# Espressif register map
File version: 1.0
CPU: Xtensa LX6 1, little endian, no MPU, FPU, 3 interrupt priority bits
Registers are 32-bit, access not given, reset 0x0 unless marked. A register's access mark holds for its fields unless they carry their own. Offsets are from the block's base; [hi:lo] are bit positions.

## I2S
Base 0x3FF4F000
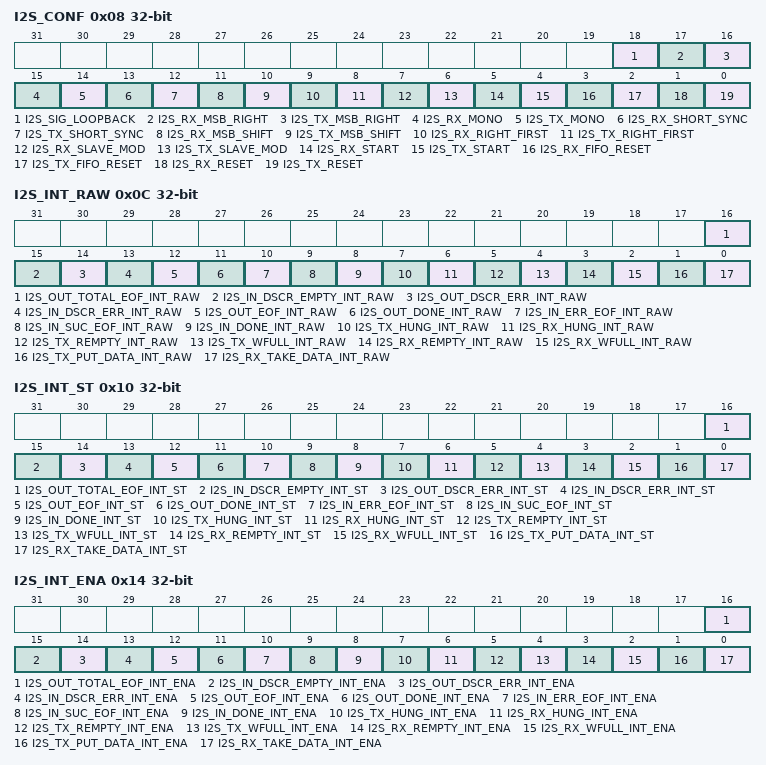
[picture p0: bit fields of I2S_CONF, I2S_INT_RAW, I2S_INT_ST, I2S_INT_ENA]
0x08 I2S_CONF
  [18] I2S_SIG_LOOPBACK, [17] I2S_RX_MSB_RIGHT, [16] I2S_TX_MSB_RIGHT, [15] I2S_RX_MONO, [14] I2S_TX_MONO, [13] I2S_RX_SHORT_SYNC, [12] I2S_TX_SHORT_SYNC, [11] I2S_RX_MSB_SHIFT, [10] I2S_TX_MSB_SHIFT, [9] I2S_RX_RIGHT_FIRST, [8] I2S_TX_RIGHT_FIRST, [7] I2S_RX_SLAVE_MOD, [6] I2S_TX_SLAVE_MOD, [5] I2S_RX_START, [4] I2S_TX_START, [3] I2S_RX_FIFO_RESET, [2] I2S_TX_FIFO_RESET, [1] I2S_RX_RESET, [0] I2S_TX_RESET
0x0C I2S_INT_RAW
  [16] I2S_OUT_TOTAL_EOF_INT_RAW, [15] I2S_IN_DSCR_EMPTY_INT_RAW, [14] I2S_OUT_DSCR_ERR_INT_RAW, [13] I2S_IN_DSCR_ERR_INT_RAW, [12] I2S_OUT_EOF_INT_RAW, [11] I2S_OUT_DONE_INT_RAW, [10] I2S_IN_ERR_EOF_INT_RAW, [9] I2S_IN_SUC_EOF_INT_RAW, [8] I2S_IN_DONE_INT_RAW, [7] I2S_TX_HUNG_INT_RAW, [6] I2S_RX_HUNG_INT_RAW, [5] I2S_TX_REMPTY_INT_RAW, [4] I2S_TX_WFULL_INT_RAW, [3] I2S_RX_REMPTY_INT_RAW, [2] I2S_RX_WFULL_INT_RAW, [1] I2S_TX_PUT_DATA_INT_RAW, [0] I2S_RX_TAKE_DATA_INT_RAW
0x10 I2S_INT_ST
  [16] I2S_OUT_TOTAL_EOF_INT_ST, [15] I2S_IN_DSCR_EMPTY_INT_ST, [14] I2S_OUT_DSCR_ERR_INT_ST, [13] I2S_IN_DSCR_ERR_INT_ST, [12] I2S_OUT_EOF_INT_ST, [11] I2S_OUT_DONE_INT_ST, [10] I2S_IN_ERR_EOF_INT_ST, [9] I2S_IN_SUC_EOF_INT_ST, [8] I2S_IN_DONE_INT_ST, [7] I2S_TX_HUNG_INT_ST, [6] I2S_RX_HUNG_INT_ST, [5] I2S_TX_REMPTY_INT_ST, [4] I2S_TX_WFULL_INT_ST, [3] I2S_RX_REMPTY_INT_ST, [2] I2S_RX_WFULL_INT_ST, [1] I2S_TX_PUT_DATA_INT_ST, [0] I2S_RX_TAKE_DATA_INT_ST
0x14 I2S_INT_ENA
  [16] I2S_OUT_TOTAL_EOF_INT_ENA, [15] I2S_IN_DSCR_EMPTY_INT_ENA, [14] I2S_OUT_DSCR_ERR_INT_ENA, [13] I2S_IN_DSCR_ERR_INT_ENA, [12] I2S_OUT_EOF_INT_ENA, [11] I2S_OUT_DONE_INT_ENA, [10] I2S_IN_ERR_EOF_INT_ENA, [9] I2S_IN_SUC_EOF_INT_ENA, [8] I2S_IN_DONE_INT_ENA, [7] I2S_TX_HUNG_INT_ENA, [6] I2S_RX_HUNG_INT_ENA, [5] I2S_TX_REMPTY_INT_ENA, [4] I2S_TX_WFULL_INT_ENA, [3] I2S_RX_REMPTY_INT_ENA, [2] I2S_RX_WFULL_INT_ENA, [1] I2S_TX_PUT_DATA_INT_ENA, [0] I2S_RX_TAKE_DATA_INT_ENA
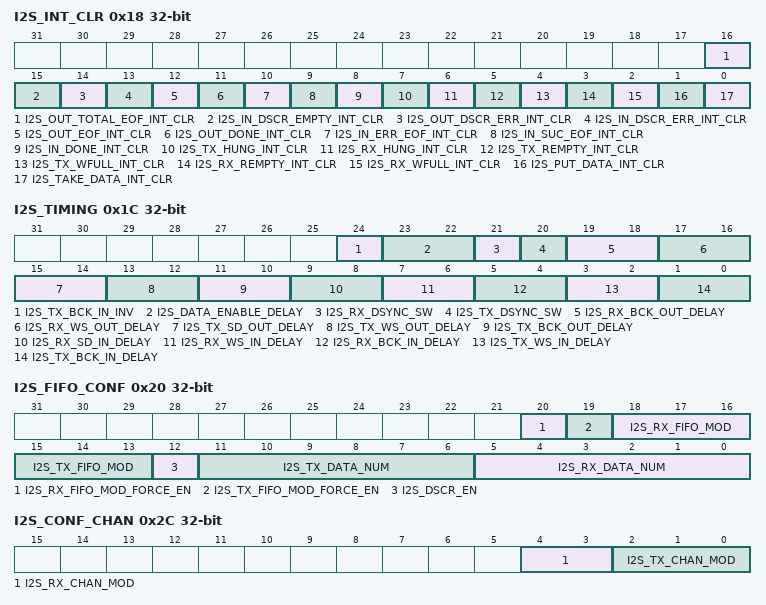
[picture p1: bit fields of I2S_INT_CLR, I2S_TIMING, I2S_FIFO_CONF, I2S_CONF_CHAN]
0x18 I2S_INT_CLR
  [16] I2S_OUT_TOTAL_EOF_INT_CLR, [15] I2S_IN_DSCR_EMPTY_INT_CLR, [14] I2S_OUT_DSCR_ERR_INT_CLR, [13] I2S_IN_DSCR_ERR_INT_CLR, [12] I2S_OUT_EOF_INT_CLR, [11] I2S_OUT_DONE_INT_CLR, [10] I2S_IN_ERR_EOF_INT_CLR, [9] I2S_IN_SUC_EOF_INT_CLR, [8] I2S_IN_DONE_INT_CLR, [7] I2S_TX_HUNG_INT_CLR, [6] I2S_RX_HUNG_INT_CLR, [5] I2S_TX_REMPTY_INT_CLR, [4] I2S_TX_WFULL_INT_CLR, [3] I2S_RX_REMPTY_INT_CLR, [2] I2S_RX_WFULL_INT_CLR, [1] I2S_PUT_DATA_INT_CLR, [0] I2S_TAKE_DATA_INT_CLR
0x1C I2S_TIMING
  [24] I2S_TX_BCK_IN_INV, [23:22] I2S_DATA_ENABLE_DELAY, [21] I2S_RX_DSYNC_SW, [20] I2S_TX_DSYNC_SW, [19:18] I2S_RX_BCK_OUT_DELAY, [17:16] I2S_RX_WS_OUT_DELAY, [15:14] I2S_TX_SD_OUT_DELAY, [13:12] I2S_TX_WS_OUT_DELAY, [11:10] I2S_TX_BCK_OUT_DELAY, [9:8] I2S_RX_SD_IN_DELAY, [7:6] I2S_RX_WS_IN_DELAY, [5:4] I2S_RX_BCK_IN_DELAY, [3:2] I2S_TX_WS_IN_DELAY, [1:0] I2S_TX_BCK_IN_DELAY
0x20 I2S_FIFO_CONF
  [20] I2S_RX_FIFO_MOD_FORCE_EN, [19] I2S_TX_FIFO_MOD_FORCE_EN, [18:16] I2S_RX_FIFO_MOD, [15:13] I2S_TX_FIFO_MOD, [12] I2S_DSCR_EN, [11:6] I2S_TX_DATA_NUM, [5:0] I2S_RX_DATA_NUM
0x24 I2S_RXEOF_NUM
  [31:0] I2S_RX_EOF_NUM
0x28 I2S_CONF_SIGLE_DATA
  [31:0] I2S_SIGLE_DATA
0x2C I2S_CONF_CHAN
  [4:3] I2S_RX_CHAN_MOD, [2:0] I2S_TX_CHAN_MOD
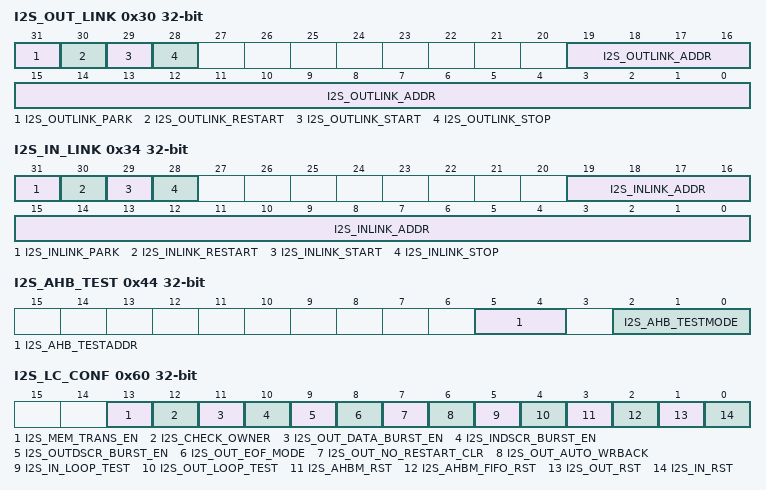
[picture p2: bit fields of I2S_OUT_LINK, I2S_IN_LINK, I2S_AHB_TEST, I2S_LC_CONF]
0x30 I2S_OUT_LINK
  [31] I2S_OUTLINK_PARK, [30] I2S_OUTLINK_RESTART, [29] I2S_OUTLINK_START, [28] I2S_OUTLINK_STOP, [19:0] I2S_OUTLINK_ADDR
0x34 I2S_IN_LINK
  [31] I2S_INLINK_PARK, [30] I2S_INLINK_RESTART, [29] I2S_INLINK_START, [28] I2S_INLINK_STOP, [19:0] I2S_INLINK_ADDR
0x38 I2S_OUT_EOF_DES_ADDR
0x3C I2S_IN_EOF_DES_ADDR
  [31:0] I2S_IN_SUC_EOF_DES_ADDR
0x40 I2S_OUT_EOF_BFR_DES_ADDR
0x44 I2S_AHB_TEST
  [5:4] I2S_AHB_TESTADDR, [2:0] I2S_AHB_TESTMODE
0x48 I2S_INLINK_DSCR
0x4C I2S_INLINK_DSCR_BF0
0x50 I2S_INLINK_DSCR_BF1
0x54 I2S_OUTLINK_DSCR
0x58 I2S_OUTLINK_DSCR_BF0
0x5C I2S_OUTLINK_DSCR_BF1
0x60 I2S_LC_CONF
  [13] I2S_MEM_TRANS_EN, [12] I2S_CHECK_OWNER, [11] I2S_OUT_DATA_BURST_EN, [10] I2S_INDSCR_BURST_EN, [9] I2S_OUTDSCR_BURST_EN, [8] I2S_OUT_EOF_MODE, [7] I2S_OUT_NO_RESTART_CLR, [6] I2S_OUT_AUTO_WRBACK, [5] I2S_IN_LOOP_TEST, [4] I2S_OUT_LOOP_TEST, [3] I2S_AHBM_RST, [2] I2S_AHBM_FIFO_RST, [1] I2S_OUT_RST, [0] I2S_IN_RST
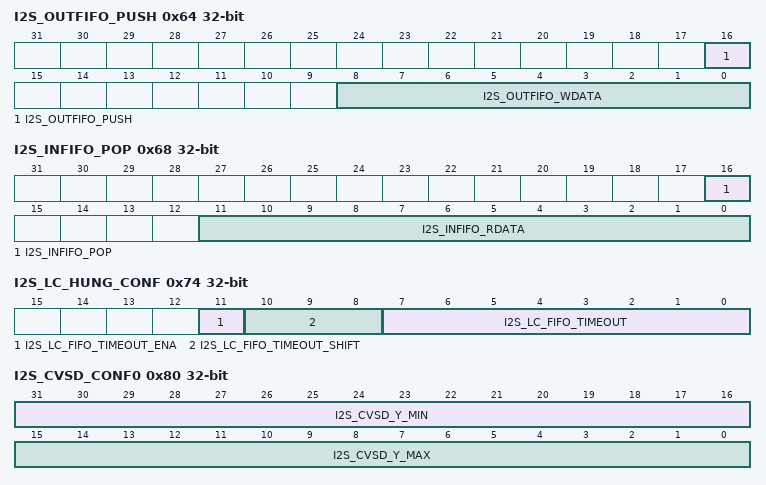
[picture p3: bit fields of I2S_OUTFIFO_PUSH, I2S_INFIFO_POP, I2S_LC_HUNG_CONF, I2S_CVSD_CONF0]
0x64 I2S_OUTFIFO_PUSH
  [16] I2S_OUTFIFO_PUSH, [8:0] I2S_OUTFIFO_WDATA
0x68 I2S_INFIFO_POP
  [16] I2S_INFIFO_POP, [11:0] I2S_INFIFO_RDATA
0x6C I2S_LC_STATE0
0x70 I2S_LC_STATE1
0x74 I2S_LC_HUNG_CONF
  [11] I2S_LC_FIFO_TIMEOUT_ENA, [10:8] I2S_LC_FIFO_TIMEOUT_SHIFT, [7:0] I2S_LC_FIFO_TIMEOUT
0x80 I2S_CVSD_CONF0
  [31:16] I2S_CVSD_Y_MIN, [15:0] I2S_CVSD_Y_MAX
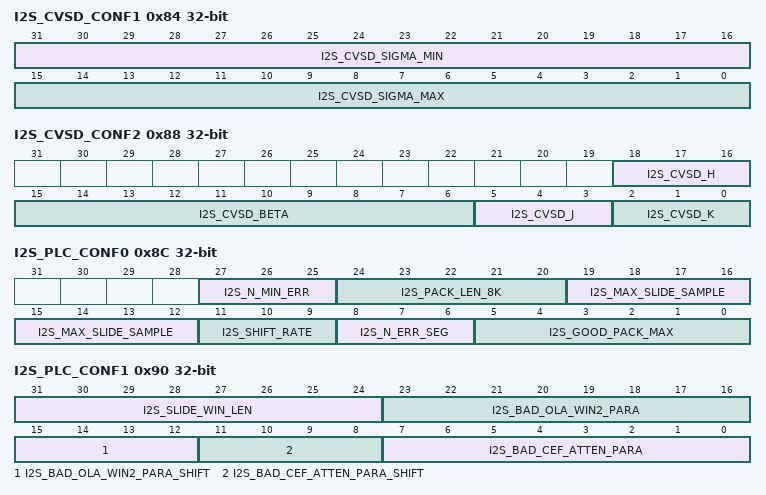
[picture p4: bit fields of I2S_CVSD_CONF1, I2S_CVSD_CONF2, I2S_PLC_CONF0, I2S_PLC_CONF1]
0x84 I2S_CVSD_CONF1
  [31:16] I2S_CVSD_SIGMA_MIN, [15:0] I2S_CVSD_SIGMA_MAX
0x88 I2S_CVSD_CONF2
  [18:16] I2S_CVSD_H, [15:6] I2S_CVSD_BETA, [5:3] I2S_CVSD_J, [2:0] I2S_CVSD_K
0x8C I2S_PLC_CONF0
  [27:25] I2S_N_MIN_ERR, [24:20] I2S_PACK_LEN_8K, [19:12] I2S_MAX_SLIDE_SAMPLE, [11:9] I2S_SHIFT_RATE, [8:6] I2S_N_ERR_SEG, [5:0] I2S_GOOD_PACK_MAX
0x90 I2S_PLC_CONF1
  [31:24] I2S_SLIDE_WIN_LEN, [23:16] I2S_BAD_OLA_WIN2_PARA, [15:12] I2S_BAD_OLA_WIN2_PARA_SHIFT, [11:8] I2S_BAD_CEF_ATTEN_PARA_SHIFT, [7:0] I2S_BAD_CEF_ATTEN_PARA
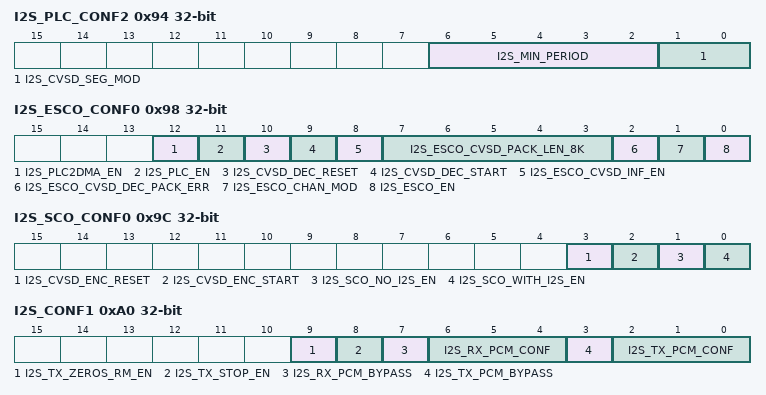
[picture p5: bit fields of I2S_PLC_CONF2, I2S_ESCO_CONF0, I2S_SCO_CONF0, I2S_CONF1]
0x94 I2S_PLC_CONF2
  [6:2] I2S_MIN_PERIOD, [1:0] I2S_CVSD_SEG_MOD
0x98 I2S_ESCO_CONF0
  [12] I2S_PLC2DMA_EN, [11] I2S_PLC_EN, [10] I2S_CVSD_DEC_RESET, [9] I2S_CVSD_DEC_START, [8] I2S_ESCO_CVSD_INF_EN, [7:3] I2S_ESCO_CVSD_PACK_LEN_8K, [2] I2S_ESCO_CVSD_DEC_PACK_ERR, [1] I2S_ESCO_CHAN_MOD, [0] I2S_ESCO_EN
0x9C I2S_SCO_CONF0
  [3] I2S_CVSD_ENC_RESET, [2] I2S_CVSD_ENC_START, [1] I2S_SCO_NO_I2S_EN, [0] I2S_SCO_WITH_I2S_EN
0xA0 I2S_CONF1
  [9] I2S_TX_ZEROS_RM_EN, [8] I2S_TX_STOP_EN, [7] I2S_RX_PCM_BYPASS, [6:4] I2S_RX_PCM_CONF, [3] I2S_TX_PCM_BYPASS, [2:0] I2S_TX_PCM_CONF
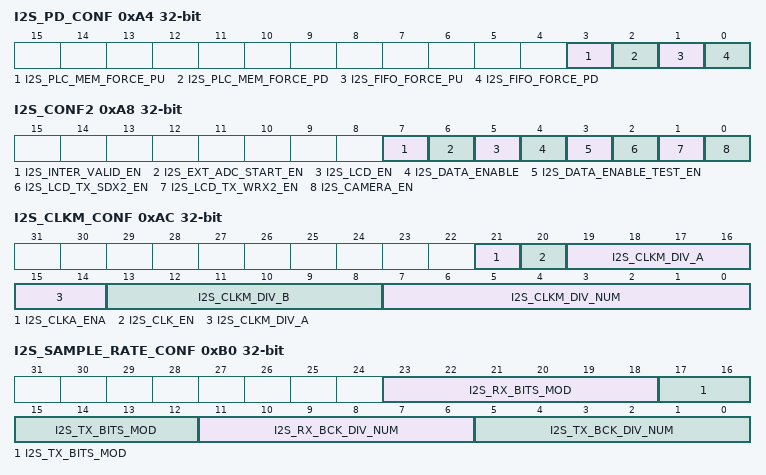
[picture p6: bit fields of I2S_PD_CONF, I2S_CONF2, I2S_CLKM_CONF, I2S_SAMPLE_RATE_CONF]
0xA4 I2S_PD_CONF
  [3] I2S_PLC_MEM_FORCE_PU, [2] I2S_PLC_MEM_FORCE_PD, [1] I2S_FIFO_FORCE_PU, [0] I2S_FIFO_FORCE_PD
0xA8 I2S_CONF2
  [7] I2S_INTER_VALID_EN, [6] I2S_EXT_ADC_START_EN, [5] I2S_LCD_EN, [4] I2S_DATA_ENABLE, [3] I2S_DATA_ENABLE_TEST_EN, [2] I2S_LCD_TX_SDX2_EN, [1] I2S_LCD_TX_WRX2_EN, [0] I2S_CAMERA_EN
0xAC I2S_CLKM_CONF
  [21] I2S_CLKA_ENA, [20] I2S_CLK_EN, [19:14] I2S_CLKM_DIV_A, [13:8] I2S_CLKM_DIV_B, [7:0] I2S_CLKM_DIV_NUM
0xB0 I2S_SAMPLE_RATE_CONF
  [23:18] I2S_RX_BITS_MOD, [17:12] I2S_TX_BITS_MOD, [11:6] I2S_RX_BCK_DIV_NUM, [5:0] I2S_TX_BCK_DIV_NUM
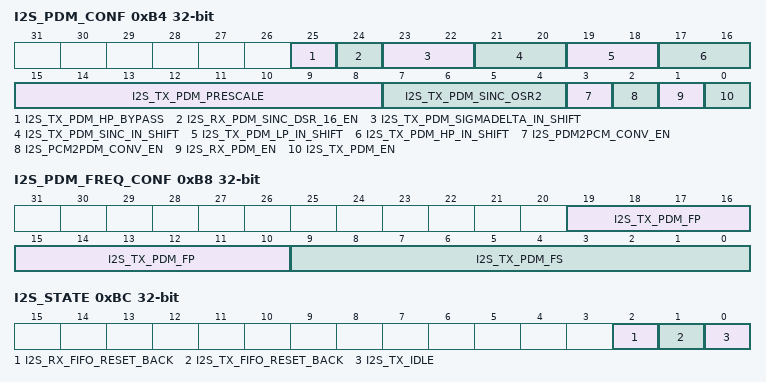
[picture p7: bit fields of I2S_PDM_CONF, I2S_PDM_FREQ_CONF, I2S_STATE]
0xB4 I2S_PDM_CONF
  [25] I2S_TX_PDM_HP_BYPASS, [24] I2S_RX_PDM_SINC_DSR_16_EN, [23:22] I2S_TX_PDM_SIGMADELTA_IN_SHIFT, [21:20] I2S_TX_PDM_SINC_IN_SHIFT, [19:18] I2S_TX_PDM_LP_IN_SHIFT, [17:16] I2S_TX_PDM_HP_IN_SHIFT, [15:8] I2S_TX_PDM_PRESCALE, [7:4] I2S_TX_PDM_SINC_OSR2, [3] I2S_PDM2PCM_CONV_EN, [2] I2S_PCM2PDM_CONV_EN, [1] I2S_RX_PDM_EN, [0] I2S_TX_PDM_EN
0xB8 I2S_PDM_FREQ_CONF
  [19:10] I2S_TX_PDM_FP, [9:0] I2S_TX_PDM_FS
0xBC I2S_STATE
  [2] I2S_RX_FIFO_RESET_BACK, [1] I2S_TX_FIFO_RESET_BACK, [0] I2S_TX_IDLE
0xFC I2S_DATE
  [31:0] I2S_I2SDATE
